# EFR32MG24A020F1536GM48 register map
Vendor: Silicon Labs; Series: EFR32; File version: B
Registers are 32-bit, read-write, reset 0x0 unless marked. A register's access mark holds for its fields unless they carry their own. Offsets are from the block's base; [hi:lo] are bit positions; {n}, {i} and the like mark numbered series; 'fields as' and 'values as' point back to an identical list.

## BURAM_NS — BURAM_NS Registers
Base 0x50080000
Same registers: BURAM_S 0x40080000
{0x0+4i} RET{i}_REG (i=0..31)
  [31:0] RETREG — Latch based Retention register

## BURTC_NS — BURTC_NS Registers
Base 0x50064000
Same registers: BURTC_S 0x40064000
0x00 IPVERSION ro reset 0x1
  [31:0] IPVERSION — IP Version ID
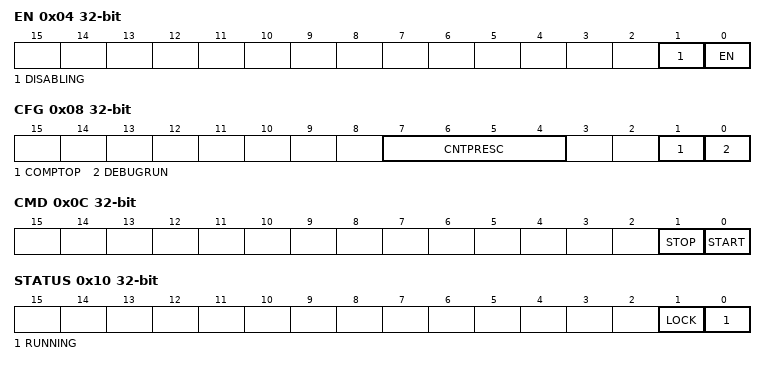
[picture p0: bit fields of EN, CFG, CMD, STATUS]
0x04 EN
  [1] DISABLING ro — Disablement busy status
  [0] EN — BURTC Enable
0x08 CFG
  [7:4] CNTPRESC — Counter prescaler value.
    0=DIV1 (CLK_CNT = (BURTC LF CLK)/1); 1=DIV2 (CLK_CNT = (BURTC LF CLK)/2); 2=DIV4 (CLK_CNT = (BURTC LF CLK)/4); 3=DIV8 (CLK_CNT = (BURTC LF CLK)/8); 4=DIV16 (CLK_CNT = (BURTC LF CLK)/16); 5=DIV32 (CLK_CNT = (BURTC LF CLK)/32); 6=DIV64 (CLK_CNT = (BURTC LF CLK)/64); 7=DIV128 (CLK_CNT = (BURTC LF CLK)/128); 8=DIV256 (CLK_CNT = (BURTC LF CLK)/256); 9=DIV512 (CLK_CNT = (BURTC LF CLK)/512); 10=DIV1024 (CLK_CNT = (BURTC LF CLK)/1024); 11=DIV2048 (CLK_CNT = (BURTC LF CLK)/2048); 12=DIV4096 (CLK_CNT = (BURTC LF CLK)/4096); 13=DIV8192 (CLK_CNT = (BURTC LF CLK)/8192); 14=DIV16384 (CLK_CNT = (BURTC LF CLK)/16384); 15=DIV32768 (CLK_CNT = (BURTC LF CLK)/32768)
  [1] COMPTOP — Compare Channel is Top Value
    0=DISABLE (The top value of the BURTC is 4294967295 (0xFFFFFFFF)); 1=ENABLE (The top value of the BURTC is given by COMP)
  [0] DEBUGRUN — Debug Mode Run Enable
    0=BURTC is frozen in debug mode; 1=BURTC is running in debug mode
0x0C CMD wo
  [1] STOP — Stop BURTC counter
  [0] START — Start BURTC counter
0x10 STATUS ro
  [1] LOCK — Configuration Lock Status
    0=UNLOCKED (All BURTC lockable registers are unlocked.); 1=LOCKED (All BURTC lockable registers are locked.)
  [0] RUNNING — BURTC running status
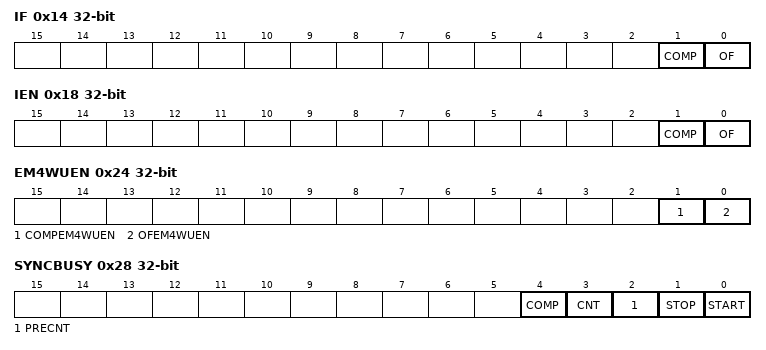
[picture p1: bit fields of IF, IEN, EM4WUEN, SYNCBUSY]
0x14 IF
  [1] COMP — Compare Match Interrupt Flag
  [0] OF — Overflow Interrupt Flag
0x18 IEN
  fields as IF
0x1C PRECNT
  [14:0] PRECNT — Pre-Counter Value
0x20 CNT
  [31:0] CNT — Counter Value
0x24 EM4WUEN
  [1] COMPEM4WUEN — Compare Match EM4 Wakeup Enable
  [0] OFEM4WUEN — Overflow EM4 Wakeup Enable
0x28 SYNCBUSY ro
  [4] COMP — Sync busy for COMP
  [3] CNT — Sync busy for CNT
  [2] PRECNT — Sync busy for PRECNT
  [1] STOP — Sync busy for STOP
  [0] START — Sync busy for START
0x2C LOCK wo reset 0xAEE8
  [15:0] LOCKKEY — Configuration Lock Key
    0xAEE8=UNLOCK (Write to unlock all BURTC lockable registers)
0x30 COMP
  [31:0] COMP — Compare Value

## DCDC_NS — DCDC_NS Registers
Base 0x50094000
Same registers: DCDC_S 0x40094000
0x00 IPVERSION ro reset 0x2
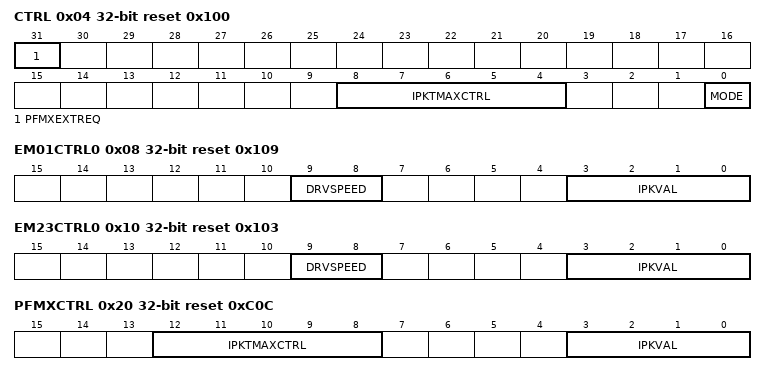
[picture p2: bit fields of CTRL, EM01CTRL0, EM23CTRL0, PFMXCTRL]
0x04 CTRL reset 0x100 — Control
  [31] PFMXEXTREQ — PFMX Enable
    0=EXTLOWLOAD (Disable PFMX mode); 1=EXTHIGHLOAD (Enable PFMX mode to support high load current)
  [8:4] IPKTMAXCTRL — Ton_max timeout control
  [0] MODE — DCDC/Bypass Mode Control
    0=BYPASS (DCDC is OFF, bypass switch is enabled); 1=DCDCREGULATION (Request DCDC regulation, bypass switch disabled)
0x08 EM01CTRL0 reset 0x109 — EM01 Configurations
  [9:8] DRVSPEED — EM01 Drive Speed Setting
    0=BEST_EMI (Not recommended for use (no benefit to this setting)); 1=DEFAULT_SETTING (Recommended for use for best efficiency and low EMI); 2=INTERMEDIATE (Not recommended for use (no benefit to this setting)); 3=BEST_EFFICIENCY (Not recommended for use (no benefit to this setting))
  [3:0] IPKVAL — EM01 Peak Current Setting
    3=Load36mA (Ipeak = 90mA, Iload = 36mA); 4=Load40mA (Ipeak = 100mA, Iload = 40mA); 5=Load44mA (Ipeak = 110mA, Iload = 44mA); 6=Load48mA (Ipeak = 120mA, Iload = 48mA); 7=Load52mA (Ipeak = 130mA, Iload = 52mA); 8=Load56mA (Ipeak = 140mA, Iload = 56mA); 9=Load60mA (Ipeak = 150mA, Iload = 60mA)
0x10 EM23CTRL0 reset 0x103 — EM23 Configurations
  [9:8] DRVSPEED — EM23 Drive Speed Setting
    values as EM01CTRL0.DRVSPEED
  [3:0] IPKVAL — EM23 Peak Current Setting
    3=Load5mA (Ipeak = 90mA, Iload = 5 mA); 9=Load10mA (Ipeak = 150mA, Iload = 10 mA)
0x20 PFMXCTRL reset 0xC0C — PFMX Control Register
  [12:8] IPKTMAXCTRL — Ton_max timeout control
  [3:0] IPKVAL — PFMX mode Peak Current Setting
    3=LOAD50MA (Ipeak = 90 mA, Iload = 50 mA); 4=LOAD65MA (Ipeak = 100 mA, Iload = 65 mA); 5=LOAD73MA (Ipeak = 110 mA, Iload = 73 mA); 6=LOAD80MA (Ipeak = 120 mA, Iload = 80 mA); 7=LOAD86MA (Ipeak = 130 mA, Iload = 86 mA); 8=LOAD93MA (Ipeak = 140 mA, Iload = 93 mA); 9=LOAD100MA (Ipeak = 150 mA, Iload = 100 mA); 10=LOAD106MA (Ipeak = 160 mA, Iload = 106 mA); 11=LOAD113MA (Ipeak = 170 mA, Iload = 113 mA); 12=LOAD120MA (Ipeak = 180 mA, Iload = 120 mA)
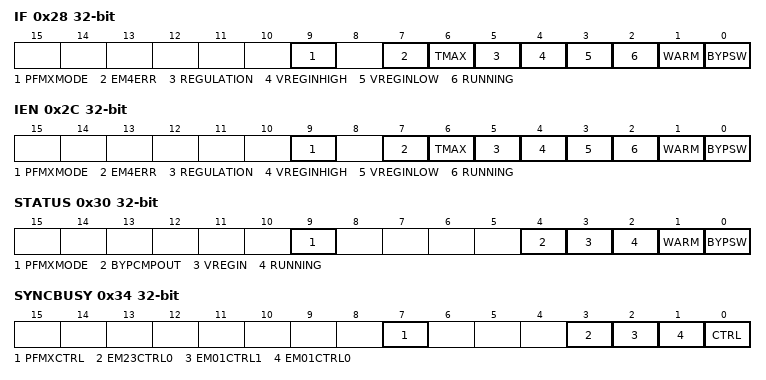
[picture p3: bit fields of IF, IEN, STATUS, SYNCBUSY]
0x28 IF — Interrupt Flags
  [9] PFMXMODE — Entered PFMX mode
  [7] EM4ERR — EM4 Entry Request Error
  [6] TMAX — Ton_max Timeout Reached
  [5] REGULATION — DCDC in regulation
  [4] VREGINHIGH — VREGIN above threshold
  [3] VREGINLOW — VREGIN below threshold
  [2] RUNNING — DCDC Running
  [1] WARM — DCDC Warmup Time Done
  [0] BYPSW — Bypass Switch Enabled
0x2C IEN — Interrupt Enable
  [9] PFMXMODE — PFMX Mode Interrupt Enable
  [7] EM4ERR — EM4 Entry Req Interrupt Enable
  [6] TMAX — Ton_max Timeout Interrupt Enable
  [5] REGULATION — DCDC in Regulation Interrupt Enable
  [4] VREGINHIGH — VREGIN above threshold Interrupt Enable
  [3] VREGINLOW — VREGIN below threshold Interrupt Enable
  [2] RUNNING — DCDC Running Interrupt Enable
  [1] WARM — DCDC Warmup Time Done Interrupt Enable
  [0] BYPSW — Bypass Switch Enabled Interrupt Enable
0x30 STATUS ro — DCDC Status Register
  [9] PFMXMODE — DCDC in PFMX mode
  [4] BYPCMPOUT — Bypass Comparator Output
  [3] VREGIN — VREGVDD comparator status
  [2] RUNNING — DCDC is running
  [1] WARM — DCDC Warmup Done
  [0] BYPSW — Bypass Switch is currently enabled
0x34 SYNCBUSY ro — Syncbusy Status Register
  [7] PFMXCTRL — PFMXCTRL Sync Busy Status
  [3] EM23CTRL0 — EM23CTRL0 Sync Busy Status
  [2] EM01CTRL1 — EM01CTRL1 Sync Bust Status
  [1] EM01CTRL0 — EM01CTRL0 Sync Busy Status
  [0] CTRL — CTRL Sync Busy Status
0x40 LOCK wo
  [15:0] LOCKKEY — Configuration Lock Key
    0xABCD=UNLOCKKEY
0x44 LOCKSTATUS ro
  [0] LOCK — Lock Status
    0=UNLOCKED (Unlocked State); 1=LOCKED (LOCKED STATE)
